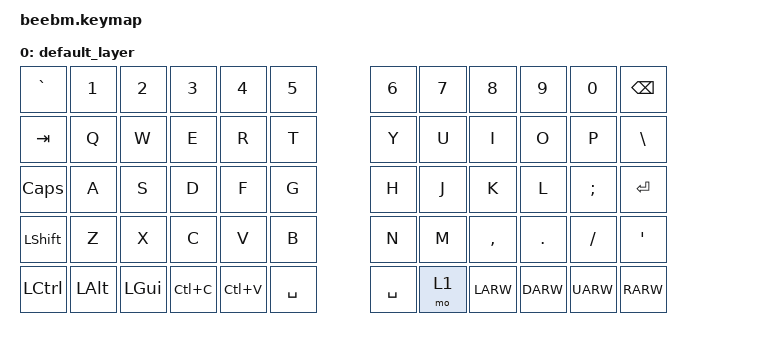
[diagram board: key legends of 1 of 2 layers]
#include <behaviors.dtsi>
#include <dt-bindings/zmk/keys.h>
#include <dt-bindings/zmk/bt.h>
#include <dt-bindings/zmk/outputs.h>

/ {
        keymap {
                compatible = "zmk,keymap";

                default_layer {
// ---------------------------------------------------------------------------------
// |   `  |  1  |  2  |  3  |  4  |  5  |     |  6  |  7  |  8  |  9  |  0  | BKSP |
// |  TAB |  Q  |  W  |  E  |  R  |  T  |     |  Y  |  U  |  I  |  O  |  P  |  \   |
// | CAPS |  A  |  S  |  D  |  F  |  G  |     |  H  |  J  |  K  |  L  |  ;  |  ENT |
// | SHFT |  Z  |  X  |  C  |  V  |  B  |     |  N  |  M  |  ,  |  .  |  /  | APOS |
// | CTRL | ALT | GUI | SPC | SPC | SPC |     | SPC | LOW |LARW |DARW |UARW | RARW |
                        bindings = <
   &kp GRAVE  &kp N1    &kp N2    &kp N3        &kp N4          &kp N5               &kp N6     &kp N7  &kp N8     &kp N9    &kp N0    &kp BSPC
   &kp TAB    &kp Q     &kp W     &kp E         &kp R           &kp T                &kp Y      &kp U   &kp I      &kp O     &kp P     &kp BSLH
   &kp CAPS   &kp A     &kp S     &kp D         &kp F           &kp G                &kp H      &kp J   &kp K      &kp L     &kp SEMI  &kp RET
   &kp LSHFT  &kp Z     &kp X     &kp C         &kp V           &kp B                &kp N      &kp M   &kp COMMA  &kp DOT   &kp FSLH  &kp APOS
   &kp LCTRL  &kp LALT  &kp LGUI  &kp LC(C)     &kp LC(V)       &kp SPACE            &kp SPACE  &mo 1   &kp LARW   &kp DARW  &kp UARW  &kp RARW
                        >;
                };
                lower_layer {
// ------------------------------------------------------------------------------------------------------------
// |  ESC  |       |    ?  |   &   |   *   |   @   |          |       |       |       |OUT_BLE| BTCLR |  DEL  |
// |  BT1  |       |       |   '   |   "   |       |          |       |   -   |   _   |   =   |   |   | PG_UP |
// |  BT2  |       |       |   (   |   )   |       |          |       |   {   |   }   |       |   :   | PG_DN |
// |  BT3  |       |       |       |       |       |          |       |       |       |       |       |       |
                        bindings = <
   &kp ESC         &trans         &kp QMARK      &kp AMPS       &kp STAR       &kp AT                 &trans    &trans          &trans          &out OUT_BLE    &bt BT_CLR      &kp DEL
   &bt BT_SEL 0    &trans         &trans         &kp SQT        &kp DQT        &trans                 &trans    &kp MINUS       &kp UNDER       &kp EQUAL       &kp PIPE        &kp PG_UP
   &bt BT_SEL 1    &trans         &trans         &kp LPAR       &kp RPAR       &trans                 &trans    &kp LBKT        &kp RBKT        &trans          &kp COLON       &kp PG_DN
   &bt BT_SEL 2    &trans         &trans         &trans         &trans         &trans                 &trans    &trans          &trans          &trans          &trans          &trans
                        >;
                };
        };
};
